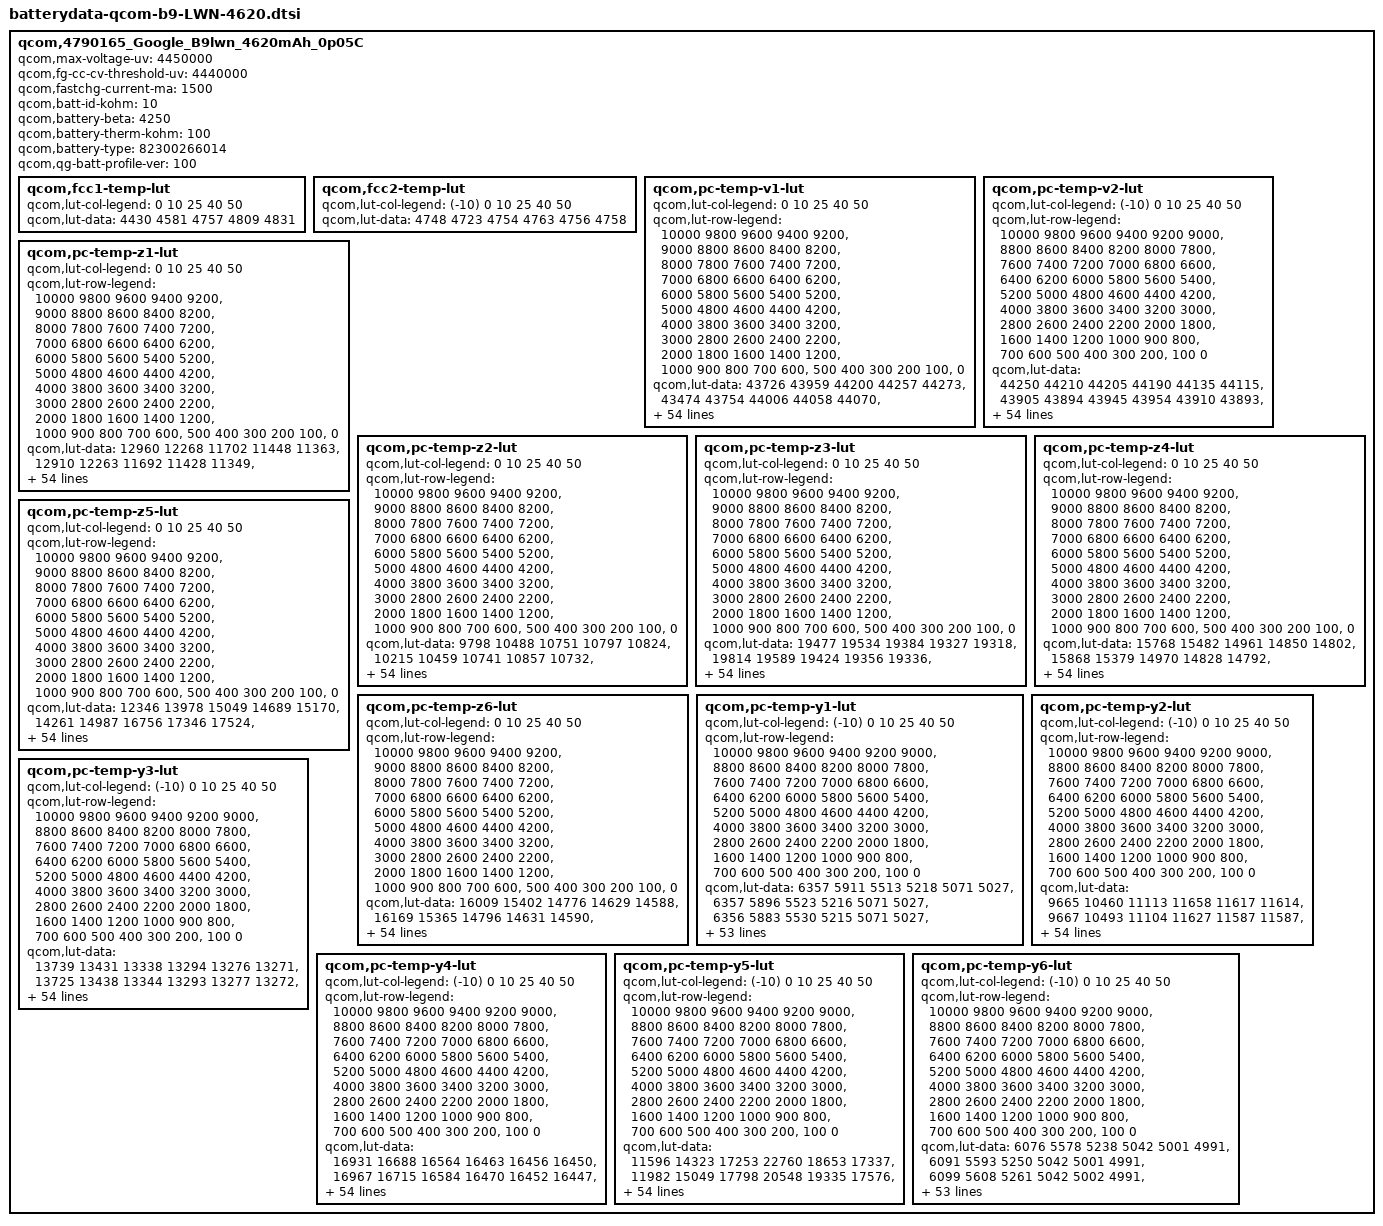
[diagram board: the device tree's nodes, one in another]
// SPDX-License-Identifier: GPL-2.0
qcom,4790165_Google_B9lwn_4620mAh_0p05C {
	/* 4790165_Google_B9lwn_4620mAh_0p05C_Oct26th2020 */
	qcom,max-voltage-uv = <4450000>;
	qcom,fg-cc-cv-threshold-uv = <4440000>;
	qcom,fastchg-current-ma = <1500>;
	qcom,batt-id-kohm = <10>;
	qcom,battery-beta = <4250>;
	qcom,battery-therm-kohm = <100>;
	qcom,battery-type = "82300266014";
	qcom,qg-batt-profile-ver = <100>;

	qcom,fcc1-temp-lut {
		qcom,lut-col-legend = <0 10 25 40 50>;
		qcom,lut-data = <4430 4581 4757 4809 4831>;
	};

	qcom,fcc2-temp-lut {
		qcom,lut-col-legend = <(-10) 0 10 25 40 50>;
		qcom,lut-data = <4748 4723 4754 4763 4756 4758>;
	};

	qcom,pc-temp-v1-lut {
		qcom,lut-col-legend = <0 10 25 40 50>;
		qcom,lut-row-legend = <10000 9800 9600 9400 9200>,
			<9000 8800 8600 8400 8200>,
			<8000 7800 7600 7400 7200>,
			<7000 6800 6600 6400 6200>,
			<6000 5800 5600 5400 5200>,
			<5000 4800 4600 4400 4200>,
			<4000 3800 3600 3400 3200>,
			<3000 2800 2600 2400 2200>,
			<2000 1800 1600 1400 1200>,
			<1000 900 800 700 600>,
			<500 400 300 200 100>,
			<0>;
		qcom,lut-data = <43726 43959 44200 44257 44273>,
			<43474 43754 44006 44058 44070>,
			<43250 43540 43804 43865 43879>,
			<43027 43315 43601 43666 43679>,
			<42795 43082 43388 43457 43477>,
			<42560 42847 43158 43236 43263>,
			<42330 42609 42919 43002 43034>,
			<42103 42371 42679 42765 42799>,
			<41880 42139 42434 42523 42558>,
			<41661 41910 42191 42279 42313>,
			<41445 41684 41952 42039 42072>,
			<41235 41461 41715 41800 41834>,
			<41033 41243 41484 41565 41599>,
			<40839 41040 41256 41332 41365>,
			<40646 40844 41035 41107 41137>,
			<40455 40650 40822 40887 40918>,
			<40272 40449 40617 40675 40706>,
			<40100 40256 40424 40476 40503>,
			<39937 40090 40237 40287 40309>,
			<39794 39939 40056 40102 40120>,
			<39678 39754 39884 39923 39940>,
			<39559 39484 39688 39736 39756>,
			<39391 39219 39418 39502 39531>,
			<39173 39047 39154 39242 39271>,
			<38984 38915 38996 39051 39067>,
			<38838 38812 38884 38912 38922>,
			<38718 38735 38775 38791 38797>,
			<38631 38668 38666 38674 38680>,
			<38566 38594 38563 38567 38573>,
			<38512 38517 38470 38470 38472>,
			<38466 38448 38384 38381 38379>,
			<38428 38384 38309 38300 38292>,
			<38388 38328 38242 38225 38214>,
			<38342 38278 38182 38156 38142>,
			<38304 38235 38132 38093 38074>,
			<38284 38194 38086 38035 38012>,
			<38272 38157 38038 37974 37943>,
			<38255 38117 37990 37914 37863>,
			<38192 38051 37929 37845 37778>,
			<38085 37946 37840 37757 37688>,
			<37968 37827 37731 37654 37590>,
			<37828 37699 37615 37539 37476>,
			<37672 37554 37484 37407 37342>,
			<37494 37377 37324 37252 37187>,
			<37335 37260 37174 37104 37043>,
			<37228 37172 37081 37012 36957>,
			<37190 37138 37054 36992 36934>,
			<37160 37114 37038 36977 36918>,
			<37131 37086 37021 36960 36904>,
			<37073 37041 36983 36918 36855>,
			<36856 36824 36769 36685 36605>,
			<36401 36385 36345 36256 36171>,
			<35826 35812 35779 35689 35604>,
			<35047 35035 35008 34920 34838>,
			<33820 33829 33827 33744 33662>,
			<30000 30000 30000 30000 30000>;
	};

	qcom,pc-temp-v2-lut {
		qcom,lut-col-legend = <(-10) 0 10 25 40 50>;
		qcom,lut-row-legend = <10000 9800 9600 9400 9200 9000>,
			<8800 8600 8400 8200 8000 7800>,
			<7600 7400 7200 7000 6800 6600>,
			<6400 6200 6000 5800 5600 5400>,
			<5200 5000 4800 4600 4400 4200>,
			<4000 3800 3600 3400 3200 3000>,
			<2800 2600 2400 2200 2000 1800>,
			<1600 1400 1200 1000 900 800>,
			<700 600 500 400 300 200>,
			<100 0>;
		qcom,lut-data = <44250 44210 44205 44190 44135 44115>,
			<43905 43894 43945 43954 43910 43893>,
			<43583 43604 43698 43723 43686 43673>,
			<43287 43346 43467 43501 43468 43456>,
			<43014 43118 43253 43286 43253 43243>,
			<42746 42886 43031 43064 43031 43023>,
			<42472 42641 42791 42828 42797 42791>,
			<42204 42393 42547 42587 42558 42553>,
			<41947 42146 42304 42346 42319 42316>,
			<41698 41901 42061 42104 42078 42077>,
			<41469 41654 41822 41865 41841 41841>,
			<41268 41390 41586 41628 41606 41607>,
			<41061 41152 41355 41396 41375 41378>,
			<40813 40993 41129 41169 41149 41152>,
			<40538 40866 40910 40948 40927 40931>,
			<40260 40684 40710 40734 40714 40717>,
			<39970 40380 40534 40525 40508 40510>,
			<39703 40065 40340 40323 40309 40311>,
			<39478 39817 40088 40141 40125 40128>,
			<39276 39591 39810 39957 39942 39944>,
			<39082 39371 39562 39732 39725 39731>,
			<38895 39156 39328 39466 39472 39485>,
			<38733 38950 39123 39229 39242 39259>,
			<38597 38743 38943 39032 39046 39060>,
			<38480 38550 38784 38859 38874 38884>,
			<38380 38407 38640 38717 38732 38742>,
			<38294 38293 38511 38594 38611 38622>,
			<38214 38201 38394 38482 38500 38511>,
			<38141 38130 38289 38376 38397 38406>,
			<38071 38068 38189 38279 38301 38309>,
			<38002 38010 38086 38189 38214 38220>,
			<37935 37956 37986 38106 38134 38138>,
			<37867 37904 37914 38031 38060 38062>,
			<37800 37851 37860 37965 37993 37996>,
			<37730 37798 37812 37899 37920 37919>,
			<37654 37741 37767 37832 37830 37811>,
			<37574 37681 37724 37763 37730 37688>,
			<37491 37615 37674 37682 37630 37578>,
			<37403 37541 37617 37593 37528 37474>,
			<37317 37457 37548 37505 37433 37378>,
			<37239 37359 37453 37425 37351 37295>,
			<37161 37247 37340 37330 37260 37202>,
			<37084 37122 37208 37209 37140 37080>,
			<37012 36991 37056 37078 37010 36948>,
			<36928 36869 36889 36926 36873 36819>,
			<36827 36769 36807 36874 36840 36786>,
			<36772 36726 36780 36865 36829 36777>,
			<36713 36685 36754 36849 36814 36762>,
			<36638 36637 36718 36825 36790 36738>,
			<36534 36555 36651 36775 36730 36664>,
			<36334 36374 36450 36574 36477 36373>,
			<35967 35993 36008 36124 36011 35898>,
			<35405 35389 35386 35521 35399 35278>,
			<34578 34544 34531 34711 34560 34419>,
			<33261 33183 33197 33492 33303 33131>,
			<29538 29510 29508 29506 29507 29506>;
	};

	qcom,pc-temp-z1-lut {
		qcom,lut-col-legend = <0 10 25 40 50>;
		qcom,lut-row-legend = <10000 9800 9600 9400 9200>,
			<9000 8800 8600 8400 8200>,
			<8000 7800 7600 7400 7200>,
			<7000 6800 6600 6400 6200>,
			<6000 5800 5600 5400 5200>,
			<5000 4800 4600 4400 4200>,
			<4000 3800 3600 3400 3200>,
			<3000 2800 2600 2400 2200>,
			<2000 1800 1600 1400 1200>,
			<1000 900 800 700 600>,
			<500 400 300 200 100>,
			<0>;
		qcom,lut-data = <12960 12268 11702 11448 11363>,
			<12910 12263 11692 11428 11349>,
			<12904 12256 11686 11416 11342>,
			<12900 12242 11679 11412 11336>,
			<12897 12226 11673 11408 11333>,
			<12896 12220 11666 11404 11331>,
			<12893 12219 11660 11400 11329>,
			<12888 12219 11655 11397 11328>,
			<12884 12212 11651 11394 11327>,
			<12876 12200 11649 11392 11326>,
			<12860 12196 11648 11391 11326>,
			<12852 12200 11647 11390 11326>,
			<12848 12207 11646 11390 11325>,
			<12841 12215 11645 11391 11325>,
			<12838 12225 11644 11391 11326>,
			<12836 12227 11643 11391 11327>,
			<12835 12211 11643 11391 11329>,
			<12831 12193 11644 11391 11331>,
			<12823 12194 11648 11394 11332>,
			<12820 12201 11651 11396 11334>,
			<12826 12205 11656 11397 11335>,
			<12834 12209 11659 11399 11336>,
			<12840 12214 11661 11402 11339>,
			<12848 12218 11663 11407 11344>,
			<12853 12224 11667 11412 11348>,
			<12859 12227 11677 11417 11351>,
			<12866 12226 11683 11421 11354>,
			<12867 12226 11687 11424 11356>,
			<12861 12230 11689 11426 11359>,
			<12856 12237 11691 11429 11362>,
			<12858 12240 11694 11432 11364>,
			<12862 12237 11696 11435 11367>,
			<12867 12234 11698 11438 11370>,
			<12875 12235 11699 11440 11373>,
			<12885 12241 11701 11443 11376>,
			<12887 12249 11705 11446 11378>,
			<12889 12262 11709 11450 11381>,
			<12892 12276 11716 11454 11385>,
			<12908 12279 11721 11457 11388>,
			<12932 12277 11723 11459 11391>,
			<12937 12275 11724 11461 11393>,
			<12935 12277 11727 11463 11394>,
			<12933 12279 11730 11466 11394>,
			<12930 12282 11734 11469 11395>,
			<12941 12280 11738 11470 11397>,
			<12926 12275 11739 11471 11398>,
			<12940 12274 11742 11471 11398>,
			<12926 12285 11745 11471 11399>,
			<12933 12285 11736 11472 11400>,
			<12952 12281 11740 11475 11403>,
			<12969 12299 11749 11479 11406>,
			<12954 12328 11754 11484 11410>,
			<12960 12327 11763 11493 11417>,
			<12987 12371 11788 11501 11426>,
			<12987 12371 11788 11501 11426>,
			<12987 12371 11788 11501 11426>;
	};

	qcom,pc-temp-z2-lut {
		qcom,lut-col-legend = <0 10 25 40 50>;
		qcom,lut-row-legend = <10000 9800 9600 9400 9200>,
			<9000 8800 8600 8400 8200>,
			<8000 7800 7600 7400 7200>,
			<7000 6800 6600 6400 6200>,
			<6000 5800 5600 5400 5200>,
			<5000 4800 4600 4400 4200>,
			<4000 3800 3600 3400 3200>,
			<3000 2800 2600 2400 2200>,
			<2000 1800 1600 1400 1200>,
			<1000 900 800 700 600>,
			<500 400 300 200 100>,
			<0>;
		qcom,lut-data = <9798 10488 10751 10797 10824>,
			<10215 10459 10741 10857 10732>,
			<10189 10429 10750 10908 10877>,
			<10166 10396 10717 10892 10979>,
			<10146 10361 10680 10861 10902>,
			<10128 10332 10638 10853 10870>,
			<10117 10306 10605 10846 10865>,
			<10110 10291 10610 10842 10862>,
			<10107 10301 10639 10837 10856>,
			<10106 10328 10665 10832 10843>,
			<10107 10348 10686 10827 10805>,
			<10108 10360 10702 10820 10715>,
			<10129 10374 10714 10806 10679>,
			<10162 10418 10722 10774 10687>,
			<10179 10509 10724 10754 10699>,
			<10187 10548 10722 10771 10716>,
			<10196 10505 10720 10794 10739>,
			<10235 10458 10731 10792 10750>,
			<10306 10462 10748 10783 10755>,
			<10312 10473 10748 10779 10760>,
			<9996 10476 10731 10792 10774>,
			<9656 10461 10709 10817 10800>,
			<9722 10441 10675 10877 10900>,
			<10069 10429 10644 10970 11118>,
			<10268 10419 10667 10988 11186>,
			<10273 10416 10741 10944 11021>,
			<10275 10429 10766 10886 10846>,
			<10281 10445 10714 10828 10787>,
			<10296 10445 10660 10771 10746>,
			<10311 10441 10648 10735 10698>,
			<10318 10439 10641 10709 10636>,
			<10323 10445 10642 10702 10610>,
			<10330 10456 10665 10751 10631>,
			<10343 10470 10694 10820 10673>,
			<10354 10491 10722 10867 10726>,
			<10315 10507 10752 10914 10801>,
			<10161 10515 10775 10952 10884>,
			<10045 10522 10792 10985 10999>,
			<10003 10536 10814 11018 11067>,
			<9973 10560 10856 11061 11055>,
			<9975 10574 10892 11098 11029>,
			<10052 10575 10893 11096 11012>,
			<10053 10577 10889 11074 11009>,
			<9881 10587 10897 11079 11006>,
			<9901 13688 10931 11081 11006>,
			<9789 10955 10967 11040 10983>,
			<9805 11648 10935 10981 10959>,
			<9830 24153 10959 10964 10941>,
			<9796 26252 10947 10978 11023>,
			<9699 26389 11037 11101 11188>,
			<9651 23430 11326 10961 10858>,
			<9574 18227 11342 10875 10742>,
			<9512 20301 11447 10803 10650>,
			<9393 17660 11327 10737 10657>,
			<9393 17660 11327 10737 10657>,
			<9393 17660 11327 10737 10657>;
	};

	qcom,pc-temp-z3-lut {
		qcom,lut-col-legend = <0 10 25 40 50>;
		qcom,lut-row-legend = <10000 9800 9600 9400 9200>,
			<9000 8800 8600 8400 8200>,
			<8000 7800 7600 7400 7200>,
			<7000 6800 6600 6400 6200>,
			<6000 5800 5600 5400 5200>,
			<5000 4800 4600 4400 4200>,
			<4000 3800 3600 3400 3200>,
			<3000 2800 2600 2400 2200>,
			<2000 1800 1600 1400 1200>,
			<1000 900 800 700 600>,
			<500 400 300 200 100>,
			<0>;
		qcom,lut-data = <19477 19534 19384 19327 19318>,
			<19814 19589 19424 19356 19336>,
			<19847 19628 19464 19384 19352>,
			<19864 19649 19475 19397 19372>,
			<19878 19664 19479 19404 19376>,
			<19889 19670 19481 19404 19376>,
			<19892 19674 19482 19402 19372>,
			<19888 19676 19478 19398 19368>,
			<19883 19667 19466 19392 19366>,
			<19881 19647 19454 19384 19364>,
			<19880 19635 19443 19375 19359>,
			<19878 19630 19434 19367 19349>,
			<19860 19625 19431 19361 19344>,
			<19835 19618 19429 19357 19343>,
			<19829 19609 19427 19356 19342>,
			<19832 19604 19425 19356 19338>,
			<19833 19602 19424 19356 19333>,
			<19831 19600 19422 19353 19330>,
			<19823 19595 19418 19344 19329>,
			<19795 19587 19417 19340 19328>,
			<19551 19585 19421 19346 19328>,
			<19295 19606 19425 19351 19329>,
			<19359 19628 19430 19351 19334>,
			<19666 19627 19434 19349 19348>,
			<19838 19617 19434 19351 19360>,
			<19836 19610 19430 19371 19372>,
			<19832 19604 19430 19387 19379>,
			<19827 19601 19446 19390 19374>,
			<19822 19604 19460 19392 19365>,
			<19815 19616 19459 19389 19359>,
			<19806 19622 19456 19378 19354>,
			<19796 19618 19451 19370 19350>,
			<19787 19611 19446 19366 19346>,
			<19783 19606 19440 19364 19341>,
			<19777 19600 19435 19362 19337>,
			<19695 19595 19431 19360 19332>,
			<19422 19590 19430 19359 19331>,
			<19262 19586 19431 19357 19333>,
			<19262 19581 19431 19355 19335>,
			<19262 19577 19428 19354 19335>,
			<19262 19572 19424 19353 19334>,
			<19262 19567 19420 19353 19333>,
			<19261 19560 19416 19352 19331>,
			<19263 19554 19411 19351 19333>,
			<19262 19383 19402 19348 19333>,
			<19263 19260 19388 19343 19323>,
			<19263 19260 19391 19336 19321>,
			<19263 19256 19378 19333 19321>,
			<19263 19256 19375 19331 19311>,
			<19264 19256 19363 19325 19306>,
			<19265 19256 19332 19338 19332>,
			<19266 19257 19335 19341 19340>,
			<19268 19256 19320 19351 19343>,
			<19272 19256 19321 19347 19331>,
			<19272 19256 19321 19347 19331>,
			<19272 19256 19321 19347 19331>;
	};

	qcom,pc-temp-z4-lut {
		qcom,lut-col-legend = <0 10 25 40 50>;
		qcom,lut-row-legend = <10000 9800 9600 9400 9200>,
			<9000 8800 8600 8400 8200>,
			<8000 7800 7600 7400 7200>,
			<7000 6800 6600 6400 6200>,
			<6000 5800 5600 5400 5200>,
			<5000 4800 4600 4400 4200>,
			<4000 3800 3600 3400 3200>,
			<3000 2800 2600 2400 2200>,
			<2000 1800 1600 1400 1200>,
			<1000 900 800 700 600>,
			<500 400 300 200 100>,
			<0>;
		qcom,lut-data = <15768 15482 14961 14850 14802>,
			<15868 15379 14970 14828 14792>,
			<15700 15282 15046 14880 14804>,
			<15515 15186 14979 14863 14819>,
			<15393 15095 14914 14824 14792>,
			<15288 15023 14870 14796 14771>,
			<15205 14962 14833 14771 14754>,
			<15138 14915 14810 14756 14741>,
			<15081 14880 14793 14749 14732>,
			<15030 14853 14781 14743 14725>,
			<14984 14836 14775 14738 14721>,
			<14948 14824 14769 14733 14717>,
			<14922 14814 14760 14727 14713>,
			<14902 14802 14749 14719 14703>,
			<14888 14789 14739 14710 14694>,
			<14877 14786 14730 14699 14688>,
			<14868 14794 14723 14688 14683>,
			<14860 14803 14718 14686 14677>,
			<14851 14796 14714 14684 14669>,
			<14864 14778 14713 14684 14666>,
			<15110 14775 14714 14685 14668>,
			<15372 14860 14718 14687 14674>,
			<15322 14954 14804 14730 14701>,
			<15061 14974 14904 14826 14765>,
			<14914 14983 14906 14847 14786>,
			<14937 14984 14877 14808 14759>,
			<14973 14955 14845 14767 14729>,
			<14979 14911 14804 14743 14718>,
			<14962 14878 14768 14724 14711>,
			<14939 14847 14751 14713 14703>,
			<14919 14830 14738 14707 14694>,
			<14898 14823 14732 14701 14687>,
			<14879 14819 14728 14691 14679>,
			<14859 14816 14726 14685 14674>,
			<14844 14814 14725 14685 14674>,
			<14912 14812 14725 14688 14676>,
			<15167 14805 14726 14692 14681>,
			<15317 14798 14731 14703 14696>,
			<15310 14796 14736 14712 14706>,
			<15295 14796 14741 14716 14705>,
			<15280 14795 14745 14718 14704>,
			<15266 14783 14740 14716 14700>,
			<15249 14767 14727 14706 14694>,
			<15226 14754 14725 14707 14695>,
			<15117 14870 14720 14708 14698>,
			<15086 14955 14694 14686 14682>,
			<15080 14948 14675 14679 14672>,
			<15073 14937 14671 14662 14653>,
			<15065 14930 14662 14646 14645>,
			<15060 14928 14675 14653 14650>,
			<15064 14940 14731 14663 14646>,
			<15090 14949 14732 14665 14643>,
			<15104 14954 14751 14655 14642>,
			<15124 14961 14751 14661 14654>,
			<15124 14961 14751 14661 14654>,
			<15124 14961 14751 14661 14654>;
	};

	qcom,pc-temp-z5-lut {
		qcom,lut-col-legend = <0 10 25 40 50>;
		qcom,lut-row-legend = <10000 9800 9600 9400 9200>,
			<9000 8800 8600 8400 8200>,
			<8000 7800 7600 7400 7200>,
			<7000 6800 6600 6400 6200>,
			<6000 5800 5600 5400 5200>,
			<5000 4800 4600 4400 4200>,
			<4000 3800 3600 3400 3200>,
			<3000 2800 2600 2400 2200>,
			<2000 1800 1600 1400 1200>,
			<1000 900 800 700 600>,
			<500 400 300 200 100>,
			<0>;
		qcom,lut-data = <12346 13978 15049 14689 15170>,
			<14261 14987 16756 17346 17524>,
			<14661 15922 17176 18052 18653>,
			<15013 16750 17621 18431 19735>,
			<15512 17523 18074 19236 20014>,
			<16066 18392 18601 19880 20110>,
			<16433 19470 19048 20486 20346>,
			<16744 20377 19214 20680 20523>,
			<17125 20844 19305 20319 20764>,
			<17710 21174 19331 19770 21070>,
			<18572 21618 18970 19235 20795>,
			<19236 22375 18566 18665 19665>,
			<19655 23035 18740 18462 19231>,
			<20101 23113 19276 18574 19929>,
			<20796 22853 19831 18851 20574>,
			<22471 22964 20588 19883 20387>,
			<23724 24157 21207 21134 19974>,
			<23762 25419 21578 21007 20000>,
			<23556 25714 21974 19881 20796>,
			<22831 25706 22681 19465 21673>,
			<17323 26414 24512 21474 22508>,
			<11665 33712 25501 23489 23136>,
			<15760 41100 25055 21766 22109>,
			<31617 39298 24158 17632 18852>,
			<40529 31937 22295 16559 17752>,
			<39554 27001 18974 17149 19044>,
			<37704 24627 17880 18059 20220>,
			<36121 23251 19550 19816 20352>,
			<34627 23963 21939 21752 20420>,
			<33215 26925 24057 22154 20701>,
			<31767 29612 26230 22159 21675>,
			<30376 31609 28061 22335 22799>,
			<29960 33233 29722 23900 24090>,
			<30519 34261 30978 26136 25250>,
			<31139 35060 31730 28224 25827>,
			<28300 35340 32306 30240 26222>,
			<17619 35042 32930 30510 26298>,
			<11280 34532 33610 28835 26035>,
			<11289 34093 33851 26925 25602>,
			<11311 33655 32235 25406 24714>,
			<11311 33246 29879 24142 23540>,
			<11279 32868 28667 23716 22949>,
			<11269 32352 27747 23623 22473>,
			<11303 31464 25768 22366 21975>,
			<11487 19748 24261 21241 20935>,
			<11502 11622 23610 22065 19544>,
			<11483 11583 25988 21127 19794>,
			<11458 11494 22782 22098 22792>,
			<11433 11478 22469 24904 22230>,
			<11453 11486 19646 21219 18881>,
			<11480 11526 14747 19685 23487>,
			<11449 11466 14461 19052 24866>,
			<11365 11417 13447 21225 24647>,
			<11278 11348 13339 19130 18714>,
			<11278 11348 13339 19130 18714>,
			<11278 11348 13339 19130 18714>;
	};

	qcom,pc-temp-z6-lut {
		qcom,lut-col-legend = <0 10 25 40 50>;
		qcom,lut-row-legend = <10000 9800 9600 9400 9200>,
			<9000 8800 8600 8400 8200>,
			<8000 7800 7600 7400 7200>,
			<7000 6800 6600 6400 6200>,
			<6000 5800 5600 5400 5200>,
			<5000 4800 4600 4400 4200>,
			<4000 3800 3600 3400 3200>,
			<3000 2800 2600 2400 2200>,
			<2000 1800 1600 1400 1200>,
			<1000 900 800 700 600>,
			<500 400 300 200 100>,
			<0>;
		qcom,lut-data = <16009 15402 14776 14629 14588>,
			<16169 15365 14796 14631 14590>,
			<16066 15323 14844 14666 14604>,
			<15951 15275 14819 14663 14618>,
			<15873 15224 14792 14651 14610>,
			<15803 15181 14772 14639 14601>,
			<15742 15145 14754 14627 14591>,
			<15688 15113 14738 14617 14583>,
			<15642 15082 14723 14610 14578>,
			<15603 15054 14711 14603 14574>,
			<15570 15036 14702 14596 14569>,
			<15539 15026 14694 14589 14562>,
			<15505 15018 14687 14583 14557>,
			<15477 15007 14681 14578 14552>,
			<15465 14995 14676 14573 14548>,
			<15460 14991 14671 14568 14543>,
			<15456 14991 14667 14564 14538>,
			<15451 14992 14663 14560 14534>,
			<15444 14987 14660 14555 14530>,
			<15436 14977 14660 14553 14529>,
			<15422 14976 14662 14556 14530>,
			<15410 15026 14668 14560 14533>,
			<15420 15080 14709 14582 14549>,
			<15460 15088 14755 14623 14587>,
			<15492 15090 14756 14633 14600>,
			<15508 15090 14745 14628 14596>,
			<15520 15076 14734 14620 14588>,
			<15520 15057 14726 14613 14582>,
			<15512 15049 14718 14606 14574>,
			<15501 15043 14711 14598 14567>,
			<15491 15039 14705 14590 14562>,
			<15479 15034 14700 14584 14556>,
			<15471 15031 14695 14578 14550>,
			<15465 15029 14692 14574 14546>,
			<15459 15027 14690 14574 14544>,
			<15448 15027 14688 14574 14543>,
			<15430 15026 14689 14575 14543>,
			<15421 15025 14693 14579 14551>,
			<15423 15026 14697 14583 14557>,
			<15426 15029 14699 14584 14557>,
			<15430 15031 14700 14586 14556>,
			<15434 15027 14697 14584 14554>,
			<15436 15022 14690 14580 14551>,
			<15437 15021 14688 14580 14553>,
			<15405 14997 14683 14580 14554>,
			<15399 14975 14666 14568 14543>,
			<15396 14973 14661 14562 14537>,
			<15396 14970 14652 14552 14529>,
			<15397 14969 14647 14544 14520>,
			<15403 14973 14648 14545 14519>,
			<15419 14987 14659 14556 14533>,
			<15443 14999 14664 14560 14537>,
			<15467 15013 14667 14563 14540>,
			<15505 15032 14673 14566 14541>,
			<15505 15032 14673 14566 14541>,
			<15505 15032 14673 14566 14541>;
	};

	qcom,pc-temp-y1-lut {
		qcom,lut-col-legend = <(-10) 0 10 25 40 50>;
		qcom,lut-row-legend = <10000 9800 9600 9400 9200 9000>,
			<8800 8600 8400 8200 8000 7800>,
			<7600 7400 7200 7000 6800 6600>,
			<6400 6200 6000 5800 5600 5400>,
			<5200 5000 4800 4600 4400 4200>,
			<4000 3800 3600 3400 3200 3000>,
			<2800 2600 2400 2200 2000 1800>,
			<1600 1400 1200 1000 900 800>,
			<700 600 500 400 300 200>,
			<100 0>;
		qcom,lut-data = <6357 5911 5513 5218 5071 5027>,
			<6357 5896 5523 5216 5071 5027>,
			<6356 5883 5530 5215 5071 5027>,
			<6356 5873 5535 5213 5070 5026>,
			<6356 5866 5537 5212 5070 5026>,
			<6356 5864 5538 5212 5069 5026>,
			<6356 5868 5535 5212 5068 5026>,
			<6357 5873 5531 5212 5067 5026>,
			<6354 5874 5532 5211 5067 5026>,
			<6348 5876 5535 5209 5067 5025>,
			<6348 5875 5538 5208 5066 5025>,
			<6364 5873 5536 5208 5066 5025>,
			<6378 5871 5534 5207 5066 5025>,
			<6372 5874 5532 5208 5066 5025>,
			<6360 5882 5528 5208 5066 5025>,
			<6360 5889 5528 5209 5065 5026>,
			<6381 5903 5529 5211 5065 5026>,
			<6396 5914 5531 5211 5065 5027>,
			<6387 5907 5532 5211 5066 5028>,
			<6372 5894 5533 5211 5068 5029>,
			<6372 5893 5534 5213 5069 5030>,
			<6381 5911 5538 5218 5069 5031>,
			<6385 5924 5542 5221 5069 5032>,
			<6379 5919 5549 5220 5071 5033>,
			<6371 5909 5554 5220 5074 5035>,
			<6370 5903 5553 5222 5076 5036>,
			<6369 5897 5550 5225 5077 5037>,
			<6370 5893 5549 5228 5078 5038>,
			<6378 5892 5551 5231 5080 5040>,
			<6386 5892 5553 5234 5083 5041>,
			<6388 5896 5555 5236 5084 5043>,
			<6390 5907 5559 5237 5085 5045>,
			<6393 5914 5558 5238 5087 5047>,
			<6399 5918 5552 5239 5090 5048>,
			<6402 5920 5548 5240 5092 5049>,
			<6400 5916 5551 5243 5093 5050>,
			<6396 5904 5557 5246 5095 5052>,
			<6391 5899 5558 5246 5096 5054>,
			<6387 5900 5556 5247 5097 5055>,
			<6385 5902 5555 5247 5098 5056>,
			<6400 5911 5553 5249 5099 5057>,
			<6411 5922 5553 5251 5101 5058>,
			<6407 5933 5556 5252 5101 5059>,
			<6403 5933 5561 5255 5102 5060>,
			<6434 5925 5570 5258 5104 5062>,
			<6440 5939 5578 5259 5105 5062>,
			<6439 5935 5572 5261 5107 5063>,
			<6455 5936 5576 5258 5106 5063>,
			<6475 5944 5571 5261 5108 5063>,
			<6510 5958 5574 5268 5108 5063>,
			<6541 5970 5573 5263 5108 5065>,
			<6558 5983 5582 5268 5112 5067>,
			<6636 6003 5596 5281 5116 5072>,
			<6642 6046 5620 5290 5122 5076>,
			<6642 6046 5620 5290 5122 5076>,
			<6642 6046 5620 5290 5122 5076>;
	};

	qcom,pc-temp-y2-lut {
		qcom,lut-col-legend = <(-10) 0 10 25 40 50>;
		qcom,lut-row-legend = <10000 9800 9600 9400 9200 9000>,
			<8800 8600 8400 8200 8000 7800>,
			<7600 7400 7200 7000 6800 6600>,
			<6400 6200 6000 5800 5600 5400>,
			<5200 5000 4800 4600 4400 4200>,
			<4000 3800 3600 3400 3200 3000>,
			<2800 2600 2400 2200 2000 1800>,
			<1600 1400 1200 1000 900 800>,
			<700 600 500 400 300 200>,
			<100 0>;
		qcom,lut-data = <9665 10460 11113 11658 11617 11614>,
			<9667 10493 11104 11627 11587 11587>,
			<9671 10540 11090 11592 11553 11553>,
			<9674 10589 11072 11553 11518 11514>,
			<9677 10628 11051 11512 11487 11473>,
			<9679 10646 11029 11467 11466 11431>,
			<9680 10650 10999 11413 11431 11381>,
			<9680 10651 10971 11365 11398 11334>,
			<9681 10647 10955 11339 11392 11301>,
			<9682 10637 10942 11319 11390 11272>,
			<9682 10638 10940 11311 11389 11260>,
			<9681 10737 10956 11308 11381 11273>,
			<9680 10837 10979 11306 11374 11293>,
			<9680 10834 11001 11307 11380 11306>,
			<9680 10817 11029 11310 11391 11320>,
			<9679 10817 11068 11322 11404 11342>,
			<9675 10876 11132 11379 11430 11378>,
			<9672 10939 11180 11432 11466 11425>,
			<9671 10969 11196 11465 11557 11525>,
			<9671 10990 11207 11488 11659 11636>,
			<9670 11001 11221 11489 11664 11671>,
			<9670 11009 11239 11485 11624 11684>,
			<9669 11011 11256 11483 11595 11681>,
			<9669 10569 11271 11504 11596 11638>,
			<9668 9887 11286 11535 11604 11595>,
			<9667 9739 11303 11559 11604 11595>,
			<9667 9713 11323 11586 11603 11607>,
			<9666 9701 11334 11612 11620 11627>,
			<9666 9695 11340 11642 11683 11685>,
			<9666 9692 11343 11662 11746 11754>,
			<9666 9689 11345 11668 11795 11812>,
			<9665 9687 11346 11672 11851 11867>,
			<9665 9685 11342 11677 11889 11913>,
			<9665 9681 11313 11695 11918 11966>,
			<9664 9677 11275 11706 11931 11993>,
			<9664 9674 11235 11698 11891 11909>,
			<9664 9672 11188 11681 11813 11771>,
			<9664 9670 11138 11661 11756 11735>,
			<9664 9668 11081 11636 11700 11744>,
			<9664 9667 11013 11625 11672 11741>,
			<9663 9666 10924 11630 11669 11706>,
			<9663 9665 10817 11632 11665 11678>,
			<9663 9664 10698 11618 11653 11671>,
			<9662 9663 10415 11586 11756 11691>,
			<9662 9663 10087 11562 11667 11669>,
			<9661 9662 9909 11518 11580 11506>,
			<9660 9661 9817 11485 11577 11403>,
			<9659 9661 9778 11458 11525 11378>,
			<9657 9660 9755 11467 11501 11416>,
			<9655 9659 9728 11418 11516 11462>,
			<9654 9658 9705 11398 11463 11330>,
			<9653 9656 9686 11333 11460 11284>,
			<9652 9653 9672 11252 11364 11214>,
			<9650 9651 9663 11150 11227 11108>,
			<9650 9651 9663 11150 11227 11108>,
			<9650 9651 9663 11150 11227 11108>;
	};

	qcom,pc-temp-y3-lut {
		qcom,lut-col-legend = <(-10) 0 10 25 40 50>;
		qcom,lut-row-legend = <10000 9800 9600 9400 9200 9000>,
			<8800 8600 8400 8200 8000 7800>,
			<7600 7400 7200 7000 6800 6600>,
			<6400 6200 6000 5800 5600 5400>,
			<5200 5000 4800 4600 4400 4200>,
			<4000 3800 3600 3400 3200 3000>,
			<2800 2600 2400 2200 2000 1800>,
			<1600 1400 1200 1000 900 800>,
			<700 600 500 400 300 200>,
			<100 0>;
		qcom,lut-data = <13739 13431 13338 13294 13276 13271>,
			<13725 13438 13344 13293 13277 13272>,
			<13710 13446 13350 13292 13279 13273>,
			<13696 13456 13355 13292 13280 13273>,
			<13683 13463 13360 13292 13281 13274>,
			<13670 13467 13363 13292 13282 13275>,
			<13658 13469 13365 13295 13283 13275>,
			<13646 13469 13367 13297 13284 13276>,
			<13637 13469 13368 13299 13285 13277>,
			<13629 13464 13370 13300 13286 13279>,
			<13621 13459 13371 13301 13286 13280>,
			<13612 13448 13369 13301 13287 13282>,
			<13606 13437 13367 13301 13287 13283>,
			<13611 13434 13365 13303 13287 13284>,
			<13621 13432 13363 13306 13286 13284>,
			<13620 13431 13362 13307 13287 13284>,
			<13591 13427 13363 13305 13289 13285>,
			<13568 13423 13363 13305 13290 13285>,
			<13566 13416 13360 13305 13291 13287>,
			<13566 13407 13353 13307 13292 13289>,
			<13567 13399 13347 13306 13291 13288>,
			<13569 13391 13343 13304 13287 13283>,
			<13571 13384 13339 13301 13284 13280>,
			<13573 13378 13336 13297 13282 13277>,
			<13576 13372 13334 13295 13280 13274>,
			<13586 13365 13331 13294 13279 13274>,
			<13609 13356 13330 13294 13278 13275>,
			<13632 13351 13328 13294 13277 13275>,
			<13656 13357 13328 13293 13277 13274>,
			<13681 13367 13327 13293 13277 13274>,
			<13708 13380 13324 13293 13277 13274>,
			<13738 13400 13319 13293 13278 13274>,
			<13769 13421 13319 13294 13279 13275>,
			<13804 13441 13321 13295 13280 13276>,
			<13840 13465 13324 13296 13281 13276>,
			<13878 13493 13326 13296 13280 13275>,
			<13916 13526 13330 13295 13279 13273>,
			<13956 13562 13333 13295 13278 13273>,
			<13997 13603 13336 13292 13277 13273>,
			<14041 13646 13340 13291 13277 13273>,
			<14090 13689 13344 13291 13277 13275>,
			<14138 13735 13347 13292 13277 13275>,
			<14179 13788 13350 13292 13278 13275>,
			<14237 13834 13350 13292 13278 13275>,
			<14206 13818 13334 13288 13274 13272>,
			<14326 13906 13351 13289 13280 13274>,
			<14426 13967 13367 13293 13281 13278>,
			<14601 14041 13382 13294 13283 13280>,
			<14842 14131 13398 13299 13288 13285>,
			<15204 14226 13423 13305 13291 13286>,
			<15751 14351 13447 13300 13285 13281>,
			<16734 14644 13487 13298 13286 13282>,
			<18782 15296 13592 13305 13288 13284>,
			<23193 16692 13809 13314 13290 13285>,
			<23193 16692 13809 13314 13290 13285>,
			<23193 16692 13809 13314 13290 13285>;
	};

	qcom,pc-temp-y4-lut {
		qcom,lut-col-legend = <(-10) 0 10 25 40 50>;
		qcom,lut-row-legend = <10000 9800 9600 9400 9200 9000>,
			<8800 8600 8400 8200 8000 7800>,
			<7600 7400 7200 7000 6800 6600>,
			<6400 6200 6000 5800 5600 5400>,
			<5200 5000 4800 4600 4400 4200>,
			<4000 3800 3600 3400 3200 3000>,
			<2800 2600 2400 2200 2000 1800>,
			<1600 1400 1200 1000 900 800>,
			<700 600 500 400 300 200>,
			<100 0>;
		qcom,lut-data = <16931 16688 16564 16463 16456 16450>,
			<16967 16715 16584 16470 16452 16447>,
			<17034 16775 16617 16476 16449 16446>,
			<17109 16844 16651 16481 16447 16445>,
			<17169 16901 16677 16484 16447 16445>,
			<17189 16921 16686 16486 16447 16445>,
			<17186 16922 16682 16485 16448 16446>,
			<17182 16923 16679 16484 16450 16448>,
			<17179 16926 16679 16486 16452 16449>,
			<17176 16935 16679 16490 16454 16451>,
			<17177 16944 16681 16495 16457 16451>,
			<17203 16954 16691 16503 16462 16453>,
			<17226 16968 16707 16511 16467 16455>,
			<17184 17020 16725 16518 16475 16459>,
			<17083 17113 16750 16525 16485 16466>,
			<17017 17131 16778 16537 16494 16473>,
			<16977 17021 16814 16558 16501 16480>,
			<16942 16904 16834 16582 16511 16488>,
			<16908 16857 16796 16611 16532 16503>,
			<16876 16824 16725 16635 16555 16518>,
			<16845 16784 16673 16624 16552 16517>,
			<16811 16736 16629 16565 16524 16504>,
			<16797 16700 16599 16518 16496 16488>,
			<16801 16677 16581 16490 16471 16466>,
			<16806 16662 16568 16473 16454 16448>,
			<16808 16662 16560 16473 16454 16448>,
			<16809 16669 16554 16473 16457 16449>,
			<16809 16676 16549 16474 16460 16451>,
			<16806 16681 16545 16479 16466 16457>,
			<16803 16685 16540 16486 16474 16465>,
			<16804 16685 16530 16492 16482 16473>,
			<16807 16686 16518 16498 16492 16481>,
			<16808 16689 16516 16506 16501 16490>,
			<16807 16698 16522 16517 16511 16501>,
			<16806 16709 16532 16522 16515 16507>,
			<16806 16718 16546 16520 16506 16494>,
			<16807 16727 16565 16517 16488 16472>,
			<16808 16734 16585 16507 16475 16462>,
			<16812 16739 16608 16487 16462 16455>,
			<16818 16741 16619 16479 16458 16453>,
			<16825 16739 16621 16482 16463 16455>,
			<16835 16732 16622 16484 16465 16456>,
			<16859 16717 16615 16484 16462 16452>,
			<16861 16707 16611 16485 16459 16451>,
			<16819 16686 16592 16465 16445 16436>,
			<16830 16695 16606 16472 16449 16446>,
			<16861 16712 16622 16479 16457 16452>,
			<16921 16736 16642 16493 16468 16464>,
			<17009 16771 16671 16509 16485 16489>,
			<17132 16806 16708 16529 16502 16499>,
			<17293 16831 16717 16519 16470 16455>,
			<17592 16896 16699 16493 16451 16445>,
			<18343 17120 16713 16498 16454 16448>,
			<20983 17845 16763 16519 16467 16460>,
			<20983 17845 16763 16519 16467 16460>,
			<20983 17845 16763 16519 16467 16460>;
	};

	qcom,pc-temp-y5-lut {
		qcom,lut-col-legend = <(-10) 0 10 25 40 50>;
		qcom,lut-row-legend = <10000 9800 9600 9400 9200 9000>,
			<8800 8600 8400 8200 8000 7800>,
			<7600 7400 7200 7000 6800 6600>,
			<6400 6200 6000 5800 5600 5400>,
			<5200 5000 4800 4600 4400 4200>,
			<4000 3800 3600 3400 3200 3000>,
			<2800 2600 2400 2200 2000 1800>,
			<1600 1400 1200 1000 900 800>,
			<700 600 500 400 300 200>,
			<100 0>;
		qcom,lut-data = <11596 14323 17253 22760 18653 17337>,
			<11982 15049 17798 20548 19335 17576>,
			<12537 15907 18304 18880 19748 17685>,
			<13121 16759 18718 17685 19952 17692>,
			<13594 17464 18990 16889 20004 17627>,
			<13817 17885 19069 16432 19962 17517>,
			<13878 18145 18968 16606 19737 17294>,
			<13928 18307 18789 16895 19386 17041>,
			<14056 18212 18577 16698 19014 17111>,
			<14313 17771 18248 16393 18557 17681>,
			<14650 17217 17821 16003 18038 17951>,
			<15122 16259 17146 15350 17433 18317>,
			<15797 15503 16533 14910 16764 18456>,
			<17357 16378 16174 14974 15891 17813>,
			<19493 18821 15906 15111 15007 16850>,
			<19582 20272 16222 15061 14830 16300>,
			<16580 20927 18870 14584 14915 15924>,
			<14427 21471 21244 14287 15023 15777>,
			<14423 22087 22185 15048 15109 15810>,
			<14476 22650 22802 16679 15234 15987>,
			<14344 22999 23077 18969 16212 16956>,
			<13878 23294 23324 22419 19474 19424>,
			<13370 23429 23417 23787 21141 20669>,
			<12774 20639 23201 23021 20933 20138>,
			<12299 15960 22903 22100 20494 19505>,
			<12243 13920 22782 21863 19904 19522>,
			<12233 12783 22711 21752 18855 19480>,
			<12241 12332 22782 21513 18108 19085>,
			<12400 12339 23835 20857 17590 17936>,
			<12613 12432 24770 20408 17306 17107>,
			<12748 12598 23153 20593 17469 17134>,
			<12866 12942 19806 21089 17959 17253>,
			<13026 13228 18984 21778 18645 17499>,
			<13310 13463 19194 22936 19914 18224>,
			<13493 13711 19406 24000 20870 18778>,
			<13497 14004 19584 24909 21243 18904>,
			<13493 14342 19802 25569 21493 19008>,
			<13426 14600 19938 25088 21365 19283>,
			<13102 14847 20179 23019 20623 19975>,
			<12849 14982 20218 21367 19760 20384>,
			<12776 14798 20083 20415 18677 20209>,
			<12691 14545 19838 19702 18167 19995>,
			<12490 14377 19120 19194 18245 19633>,
			<12686 13980 17833 19143 19094 19667>,
			<12843 13450 14605 18752 17784 19572>,
			<13069 13527 14529 17789 19641 17238>,
			<12984 13516 14548 19091 18184 18418>,
			<12904 13618 14676 17613 17177 18261>,
			<12608 13806 14591 17466 18549 19189>,
			<12439 14109 14768 18349 19683 19262>,
			<11837 14344 14494 17491 18517 19842>,
			<10792 13245 14167 18382 21409 23254>,
			<9957 11519 14289 20494 22589 23718>,
			<9308 10247 13963 24045 23734 23990>,
			<9308 10247 13963 24045 23734 23990>,
			<9308 10247 13963 24045 23734 23990>;
	};

	qcom,pc-temp-y6-lut {
		qcom,lut-col-legend = <(-10) 0 10 25 40 50>;
		qcom,lut-row-legend = <10000 9800 9600 9400 9200 9000>,
			<8800 8600 8400 8200 8000 7800>,
			<7600 7400 7200 7000 6800 6600>,
			<6400 6200 6000 5800 5600 5400>,
			<5200 5000 4800 4600 4400 4200>,
			<4000 3800 3600 3400 3200 3000>,
			<2800 2600 2400 2200 2000 1800>,
			<1600 1400 1200 1000 900 800>,
			<700 600 500 400 300 200>,
			<100 0>;
		qcom,lut-data = <6076 5578 5238 5042 5001 4991>,
			<6091 5593 5250 5042 5001 4991>,
			<6099 5608 5261 5042 5002 4991>,
			<6104 5622 5269 5043 5002 4992>,
			<6105 5632 5274 5043 5003 4992>,
			<6105 5636 5275 5044 5004 4993>,
			<6094 5633 5272 5045 5004 4994>,
			<6079 5629 5268 5046 5005 4995>,
			<6069 5626 5265 5047 5006 4996>,
			<6062 5622 5263 5049 5008 4997>,
			<6059 5618 5262 5051 5009 4999>,
			<6061 5611 5262 5053 5011 5001>,
			<6062 5605 5262 5055 5013 5002>,
			<6055 5616 5264 5058 5015 5004>,
			<6035 5643 5268 5062 5017 5006>,
			<6014 5649 5273 5067 5020 5008>,
			<5988 5620 5283 5072 5024 5011>,
			<5969 5587 5289 5077 5028 5014>,
			<5962 5571 5276 5086 5035 5019>,
			<5957 5559 5251 5094 5041 5024>,
			<5953 5547 5233 5090 5040 5024>,
			<5949 5536 5217 5072 5029 5017>,
			<5948 5525 5207 5056 5018 5009>,
			<5953 5512 5201 5046 5009 5000>,
			<5963 5500 5198 5040 5003 4994>,
			<5975 5500 5196 5040 5003 4994>,
			<5992 5505 5195 5040 5003 4994>,
			<6011 5513 5194 5041 5004 4995>,
			<6029 5527 5196 5042 5005 4997>,
			<6050 5546 5197 5044 5008 4999>,
			<6071 5567 5195 5046 5010 5001>,
			<6095 5590 5193 5049 5014 5004>,
			<6120 5616 5193 5052 5018 5007>,
			<6148 5644 5200 5057 5021 5011>,
			<6177 5675 5210 5059 5023 5013>,
			<6208 5709 5222 5059 5020 5008>,
			<6241 5744 5236 5059 5015 5001>,
			<6275 5782 5253 5056 5010 4998>,
			<6309 5823 5272 5049 5006 4997>,
			<6346 5864 5291 5046 5005 4996>,
			<6388 5903 5309 5048 5006 4998>,
			<6433 5942 5327 5049 5007 4999>,
			<6476 5983 5347 5050 5007 4998>,
			<6525 6024 5360 5051 5007 4997>,
			<6504 6013 5336 5044 5000 4992>,
			<6606 6092 5377 5047 5005 4996>,
			<6705 6147 5402 5053 5009 5001>,
			<6885 6215 5431 5058 5013 5006>,
			<7122 6299 5465 5066 5022 5016>,
			<7469 6391 5509 5076 5029 5020>,
			<7972 6507 5546 5071 5016 5004>,
			<8866 6792 5601 5064 5011 5002>,
			<10664 7403 5728 5071 5014 5005>,
			<14604 8675 5957 5087 5021 5010>,
			<14604 8675 5957 5087 5021 5010>,
			<14604 8675 5957 5087 5021 5010>;
	};

};
